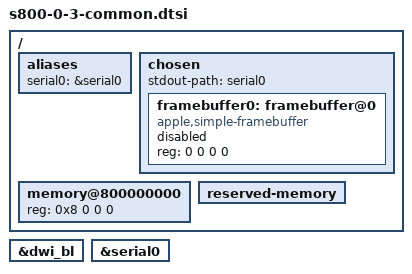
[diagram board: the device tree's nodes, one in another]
// SPDX-License-Identifier: GPL-2.0+ OR MIT
/*
 * Apple iPhone 6s, iPhone 6s Plus, iPad 5, iPhone SE
 *
 * This file contains parts common to all Apple A9 devices.
 *
 * target-type: J71s, J72s, N66, N69u, N71, J71t, J72t, N66m, N69, N71m
 *
 * Copyright (c) 2024, Nick Chan <towinchenmi@gmail.com>
 */

/ {
	aliases {
		serial0 = &serial0;
	};

	chosen {
		#address-cells = <2>;
		#size-cells = <2>;
		ranges;

		stdout-path = "serial0";

		framebuffer0: framebuffer@0 {
			compatible = "apple,simple-framebuffer", "simple-framebuffer";
			reg = <0 0 0 0>; /* To be filled by loader */
			/* Format properties will be added by loader */
			status = "disabled";
		};
	};

	memory@800000000 {
		device_type = "memory";
		reg = <0x8 0 0 0>; /* To be filled by loader */
	};

	reserved-memory {
		#address-cells = <2>;
		#size-cells = <2>;
		ranges;

		/* To be filled by loader */
	};
};

&dwi_bl {
	status = "okay";
};

&serial0 {
	status = "okay";
};
